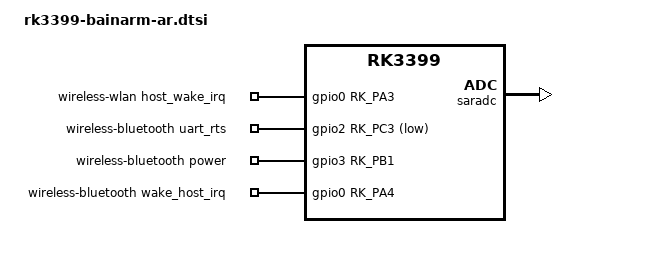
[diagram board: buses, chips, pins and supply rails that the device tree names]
/*
 * Copyright (c) 2016 Fuzhou Rockchip Electronics Co., Ltd
 *
 * This file is dual-licensed: you can use it either under the terms
 * of the GPL or the X11 license, at your option. Note that this dual
 * licensing only applies to this file, and not this project as a
 * whole.
 *
 *  a) This file is free software; you can redistribute it and/or
 *     modify it under the terms of the GNU General Public License as
 *     published by the Free Software Foundation; either version 2 of the
 *     License, or (at your option) any later version.
 *
 *     This file is distributed in the hope that it will be useful,
 *     but WITHOUT ANY WARRANTY; without even the implied warranty of
 *     MERCHANTABILITY or FITNESS FOR A PARTICULAR PURPOSE.  See the
 *     GNU General Public License for more details.
 *
 * Or, alternatively,
 *
 *  b) Permission is hereby granted, free of charge, to any person
 *     obtaining a copy of this software and associated documentation
 *     files (the "Software"), to deal in the Software without
 *     restriction, including without limitation the rights to use,
 *     copy, modify, merge, publish, distribute, sublicense, and/or
 *     sell copies of the Software, and to permit persons to whom the
 *     Software is furnished to do so, subject to the following
 *     conditions:
 *
 *     The above copyright notice and this permission notice shall be
 *     included in all copies or substantial portions of the Software.
 *
 *     THE SOFTWARE IS PROVIDED "AS IS", WITHOUT WARRANTY OF ANY KIND,
 *     EXPRESS OR IMPLIED, INCLUDING BUT NOT LIMITED TO THE WARRANTIES
 *     OF MERCHANTABILITY, FITNESS FOR A PARTICULAR PURPOSE AND
 *     NONINFRINGEMENT. IN NO EVENT SHALL THE AUTHORS OR COPYRIGHT
 *     HOLDERS BE LIABLE FOR ANY CLAIM, DAMAGES OR OTHER LIABILITY,
 *     WHETHER IN AN ACTION OF CONTRACT, TORT OR OTHERWISE, ARISING
 *     FROM, OUT OF OR IN CONNECTION WITH THE SOFTWARE OR THE USE OR
 *     OTHER DEALINGS IN THE SOFTWARE.
 */

#include "rk3399-bainarm.dtsi"

/ {
	compatible = "rockchip,rk3399-bainarm-ar", "rockchip,rk3399";

	rt5651-sound {
		compatible = "simple-audio-card";
		simple-audio-card,format = "i2s";
		simple-audio-card,name = "realtek,rt5651-codec";
		simple-audio-card,mclk-fs = <256>;
		simple-audio-card,widgets =
			"Microphone", "Mic Jack",
			"Headphone", "Headphone Jack";
		simple-audio-card,routing =
			"Mic Jack", "MICBIAS1",
			"IN1P", "Mic Jack",
			"Headphone Jack", "HPOL",
			"Headphone Jack", "HPOR";
		simple-audio-card,cpu {
			sound-dai = <&i2s0>;
		};
		simple-audio-card,codec {
			sound-dai = <&rt5651>;
		};
	};

	wireless-wlan {
		compatible = "wlan-platdata";
		rockchip,grf = <&grf>;
		wifi_chip_type = "ap6354";
		sdio_vref = <1800>;
		WIFI,host_wake_irq = <&gpio0 RK_PA3 GPIO_ACTIVE_HIGH>;
		status = "okay";
	};

	wireless-bluetooth {
		compatible = "bluetooth-platdata";
		clocks = <&rk818 1>;
		clock-names = "ext_clock";
		uart_rts_gpios = <&gpio2 RK_PC3 GPIO_ACTIVE_LOW>;
		pinctrl-names = "default", "rts_gpio";
		pinctrl-0 = <&uart0_rts>;
		pinctrl-1 = <&uart0_rts_gpio>;
		BT,power_gpio  = <&gpio3 RK_PB1 GPIO_ACTIVE_HIGH>;
		BT,wake_host_irq = <&gpio0 RK_PA4 GPIO_ACTIVE_HIGH>;
		status = "okay";
	};
};

&saradc {
	status = "okay";
};

&rockchip_suspend {
	status = "okay";
	rockchip,sleep-debug-en = <1>;
	rockchip,sleep-mode-config = <
		(0
		| RKPM_SLP_ARMPD
		| RKPM_SLP_PERILPPD
		| RKPM_SLP_DDR_RET
		| RKPM_SLP_PLLPD
		| RKPM_SLP_CENTER_PD
		| RKPM_SLP_AP_PWROFF
		)
		>;
	rockchip,wakeup-config = <
		(0
		| RKPM_GPIO_WKUP_EN
		| RKPM_PWM_WKUP_EN
		)
		>;
		rockchip,pwm-regulator-config = <
		(0
		| PWM2_REGULATOR_EN
		)
		>;
		rockchip,power-ctrl =
		<&gpio1 17 GPIO_ACTIVE_HIGH>,
		<&gpio1 14 GPIO_ACTIVE_HIGH>;
};

&pinctrl {
	sdio-pwrseq {
		wifi_enable_h: wifi-enable-h {
			rockchip,pins =
				<0 RK_PB2 RK_FUNC_GPIO &pcfg_pull_none>;
		};
	};

	wireless-bluetooth {
		uart0_rts_gpio: uart0-rts-gpio {
			rockchip,pins =
				<2 RK_PC3 RK_FUNC_GPIO &pcfg_pull_none>;
		};
	};
};
